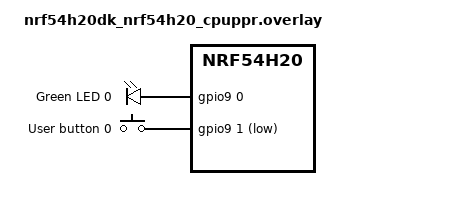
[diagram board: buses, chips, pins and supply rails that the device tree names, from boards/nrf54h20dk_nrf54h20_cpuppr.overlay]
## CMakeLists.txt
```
# SPDX-License-Identifier: Apache-2.0

cmake_minimum_required(VERSION 3.20.0)
find_package(Zephyr REQUIRED HINTS $ENV{ZEPHYR_BASE})
project(VS_Code)

# BLE 低功耗从机用 main2.c；按钮 demo 用 main.c（需改回 main.c 再编译）
target_sources(app PRIVATE src/main.c)
```

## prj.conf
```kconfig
# 关闭串口和控制台，降低功耗（板级默认启用了 UART）
CONFIG_SERIAL=n
CONFIG_CONSOLE=n
CONFIG_UART_CONSOLE=n

# GPIO HAL 依赖（P0 引脚控制）
CONFIG_GPIO=y
```

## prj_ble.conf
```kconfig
# BLE 从机 — 极致低功耗（main2.c 用）
#
# 必须用本文件构建，否则会报 undefined reference to bt_gatt_attr_read_service / bt_gatt_attr_read_chrc：
#   west build -b <board> -- -DCONFIG_FILE=prj_ble.conf
# 且不要使用“关闭 RADIO”的 overlay。
#
CONFIG_BT=y
CONFIG_BT_HOST=y
CONFIG_BT_PERIPHERAL=y
CONFIG_BT_GATT_SERVER=y
CONFIG_BT_DEVICE_NAME="IOTrigger"
CONFIG_BT_MAX_CONN=1
CONFIG_BT_MAX_PAIRED=0

# 长连接间隔 + Slave Latency，由代码里 bt_conn_param_update 请求
CONFIG_BT_CONN_PARAM_UPDATE=y

# 关闭串口/控制台
CONFIG_SERIAL=n
CONFIG_CONSOLE=n
CONFIG_UART_CONSOLE=n

# 不启用 GPIO/TIMER/GPIOTE 等（IO 由你处理）
# CONFIG_GPIO 按需保留，若你只在应用里用 HAL 操作 P0 可不依赖 Zephyr GPIO
```

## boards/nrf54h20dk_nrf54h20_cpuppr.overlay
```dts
/* SPDX-License-Identifier: Apache-2.0 */

#include <zephyr/dt-bindings/gpio/gpio.h>
#include <zephyr/dt-bindings/input/input-event-codes.h>

/ {
	aliases {
		led0 = &led0;
		button0 = &button_0;
	};

	leds {
		compatible = "gpio-leds";
		led0: led_0 {
			gpios = <&gpio9 0 GPIO_ACTIVE_HIGH>;
			label = "Green LED 0";
		};
	};

	gpio_keys {
		compatible = "gpio-keys";
		button_0: button_0 {
			label = "User button 0";
			/* 上拉 + 低电平有效（按下时接地） */
			gpios = <&gpio9 1 (GPIO_PULL_UP | GPIO_ACTIVE_LOW)>;
			zephyr,code = <INPUT_KEY_0>;
		};
	};
};

&gpiote130 {
	status = "okay";
};

&gpio9 {
	status = "okay";
};
```

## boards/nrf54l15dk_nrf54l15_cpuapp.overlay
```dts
/*
 * 默认 overlay：不关闭 RADIO，供 main2.c（BLE 从机）使用。
 * 构建 main.c 按钮 demo 且要关 RADIO 时请用：
 *   -DOVERLAY_FILE=boards/nrf54l15dk_nrf54l15_cpuapp_button.overlay
 */

/*
 * 让 P1.13（BUTTON0）使用低功耗 SENSE 边沿检测
 * 而非 GPIOTE 通道（GPIOTE 通道需要 HFCLK 持续运行 ~300µA）
 * SENSE 机制使用 32.768kHz 时钟采样，空闲时 HFCLK 可关闭
 * BIT(13) = 0x2000
 */
&gpio1 {
	sense-edge-mask = <0x2000>;
};
```

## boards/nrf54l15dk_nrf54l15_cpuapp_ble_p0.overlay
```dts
/*
 * BLE 控制 P0.04 翻转用 overlay
 * 不关闭 RADIO/BT，不启用 PERI 域 TIMER20/21、GPIOTE20
 * P0.04 通过 LP 域（gpio0）控制
 */
/ {
	aliases {
		led-p0-04 = &led_p0_04;
	};
	led_p0_04: led_p0_04 {
		compatible = "gpio-leds";
		gpios = <&gpio0 4 GPIO_ACTIVE_HIGH>;
	};
};

/* 不启用 PERI 域定时器/GPIOTE20，保持与主 overlay 的 sense-edge 等可按需叠加 */
```

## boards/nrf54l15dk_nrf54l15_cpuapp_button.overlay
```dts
/* 关闭 RADIO，仅用于 main.c 按钮低功耗 demo */

&radio {
	status = "disabled";
};

&ieee802154 {
	status = "disabled";
};

&bt_hci_sdc {
	status = "disabled";
};
```

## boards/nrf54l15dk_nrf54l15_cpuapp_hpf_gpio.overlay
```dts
/*
 * Copyright (c) 2024 Nordic Semiconductor ASA
 *
 * SPDX-License-Identifier: LicenseRef-Nordic-5-Clause
 */

#include <zephyr/dt-bindings/gpio/gpio.h>
#include <zephyr/dt-bindings/input/input-event-codes.h>

&led0 {
	gpios = <&hpf_gpio 9 GPIO_ACTIVE_HIGH>;
};

/ {
	aliases {
		button0 = &button_0;
	};

	gpio_keys {
		compatible = "gpio-keys";
		button_0: button_0 {
			label = "User button 0";
			/* 上拉 + 低电平有效（按下时接地） */
			gpios = <&hpf_gpio 8 (GPIO_PULL_UP | GPIO_ACTIVE_LOW)>;
			zephyr,code = <INPUT_KEY_0>;
		};
	};
};
```

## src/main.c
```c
/*
 * 极致低功耗 LP 域定时器触发 P0.04 翻转
 *
 * 功能：
 *   GRTC（LP 域全局实时计数器）每 3s 触发一次翻转序列
 *   每次序列：P0.04 每 300ms 翻转一次，共 6 次
 *   定时间隔、翻转间隔、翻转次数均为变量可调
 *
 * 电源域分析（nRF54L15 Datasheet §Power domains）：
 *   ┌─────────┬─────────────────────────────────────┬──────────┐
 *   │ 域      │ 外设                                │ 本方案   │
 *   ├─────────┼─────────────────────────────────────┼──────────┤
 *   │ MCU (0) │ CPU, CACHE                          │ 必须     │
 *   │ RADIO(1)│ RADIO                               │ 不启用   │
 *   │ PERI (2)│ TIMER20-24, GPIOTE20, UART/SPI, P1 │ 不启用   │
 *   │ LP  (3) │ GRTC, P0                            │ ★ 使用   │
 *   └─────────┴─────────────────────────────────────┴──────────┘
 *
 * 功耗优化策略：
 *   - GRTC 运行在 LFCLK（32.768kHz），无需 HFCLK
 *   - P0.04 属于 LP 域，直接 GPIO HAL 翻转
 *   - 空闲时 System ON IDLE（约 2.9µA with GRTC + 256KB RAM）
 *   - 不启用 PERI 域（无 TIMER20/21、GPIOTE20、HFCLK）
 *
 * CPU 介入分析（每 ~4.8s 周期）：
 *   3s 休眠结束 → 中断 1 次（启动翻转序列）
 *   300ms × 6 翻转 → 中断 6 次（GPIO toggle + 计数，~2µs/次）
 *   共 7 次唤醒，总 CPU 时间 ~14µs / 4.8s
 *
 * 注：GRTC 是全局外设（base 0x400E2000），其 PUBLISH 寄存器不直接
 *     连接 DPPIC30，无法用 DPPI30 → GPIOTE30 实现纯硬件翻转。
 *     由于 CPU 已因计数需求而唤醒，ISR 中直接 toggle 是等效最优解。
 */

#include <zephyr/kernel.h>
#include <zephyr/drivers/timer/nrf_grtc_timer.h>
#include <hal/nrf_gpio.h>

/* ===== 可配置参数（运行时可调） ===== */
static uint32_t cycle_interval_ms  = 3000;  /* 周期间隔，默认 3s */
static uint32_t toggle_interval_ms = 300;   /* 翻转间隔，默认 300ms */
static uint32_t toggle_count       = 6;     /* 每周期翻转次数 */

/* ===== 引脚定义（LP 域） ===== */
#define OUTPUT_PIN    NRF_GPIO_PIN_MAP(0, 1) /* P0.01，属于 LP 域 */

/* ===== GRTC 频率（SYSCOUNTER 运行在 1 MHz） ===== */
#define GRTC_FREQ_HZ  1000000UL

/* ===== 内部状态 ===== */
static int32_t  grtc_chan;          /* Zephyr 分配的 GRTC CC 通道 */
static volatile uint32_t remaining; /* 剩余翻转次数 */

/* 毫秒转 GRTC ticks（1 MHz → 1 tick = 1µs） */
#define MS_TO_TICKS(ms) ((uint64_t)(ms) * (GRTC_FREQ_HZ / 1000))

/* 前向声明 */
static void on_cycle_compare(int32_t id, uint64_t exp, void *ctx);
static void on_toggle_compare(int32_t id, uint64_t exp, void *ctx);

/* ================================================================
 * on_cycle_compare() — 周期到达，启动翻转序列
 *
 * 3s 定时到期 → 初始化翻转计数 → 设置首次翻转 CC
 * ================================================================ */
static void on_cycle_compare(int32_t id, uint64_t exp, void *ctx)
{
	ARG_UNUSED(id);
	ARG_UNUSED(ctx);

	remaining = toggle_count;

	/* 第一次翻转在 toggle_interval_ms 后 */
	z_nrf_grtc_timer_set(grtc_chan,
		exp + MS_TO_TICKS(toggle_interval_ms),
		on_toggle_compare, NULL);
}

/* ================================================================
 * on_toggle_compare() — 每次翻转的 GRTC compare 回调
 *
 * 每次 ~2µs：GPIO toggle（1 指令）+ 计数 + 设置下次 CC
 * ================================================================ */
static void on_toggle_compare(int32_t id, uint64_t exp, void *ctx)
{
	ARG_UNUSED(id);
	ARG_UNUSED(ctx);

	nrf_gpio_pin_toggle(OUTPUT_PIN);
	remaining--;

	if (remaining > 0) {
		/* 下一次翻转 */
		z_nrf_grtc_timer_set(grtc_chan,
			exp + MS_TO_TICKS(toggle_interval_ms),
			on_toggle_compare, NULL);
	} else {
		/* 翻转序列完成：确保 P0.04 归低（偶数次已为低，奇数次强制拉低） */
		nrf_gpio_pin_clear(OUTPUT_PIN);

		/* 设置下一个周期 */
		z_nrf_grtc_timer_set(grtc_chan,
			exp + MS_TO_TICKS(cycle_interval_ms),
			on_cycle_compare, NULL);
	}
}

/* ================================================================ */
int main(void)
{
	/* P0.04 默认输出低电平 */
	nrf_gpio_cfg_output(OUTPUT_PIN);
	nrf_gpio_pin_clear(OUTPUT_PIN);

	/* 分配 GRTC CC 通道（Zephyr 管理，避免与系统定时器冲突） */
	grtc_chan = z_nrf_grtc_timer_chan_alloc();
	if (grtc_chan < 0) {
		return -1;
	}

	/* 启动第一个周期定时 */
	uint64_t now = z_nrf_grtc_timer_read();

	z_nrf_grtc_timer_set(grtc_chan,
		now + MS_TO_TICKS(cycle_interval_ms),
		on_cycle_compare, NULL);

	/* CPU 进入永久休眠（由 GRTC compare 中断唤醒） */
	k_sleep(K_FOREVER);
	return 0;
}
```

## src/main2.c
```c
/*
 * 极致低功耗 BLE 从机 — 手机写 GATT 触发（IO 由你处理）
 *
 * 功能：广播 + 可连接，一个自定义 Service + 一个 Write 特征。
 *       手机写入该特征时触发（回调里不操作 IO，你在别处处理）。
 * 功耗：长连接间隔 800ms + Slave Latency 4，无串口/控制台。
 */

#include <zephyr/kernel.h>
#include <zephyr/bluetooth/bluetooth.h>
#include <zephyr/bluetooth/conn.h>
#include <zephyr/bluetooth/gatt.h>
#include <zephyr/bluetooth/uuid.h>

/* 自定义 Service / Characteristic UUID（16-bit 便于 nRF Connect 识别） */
#define BT_UUID_IO_TRIGGER_SVC_VAL  0x1234
#define BT_UUID_IO_TRIGGER_CHRC_VAL 0x1235

#define BT_UUID_IO_TRIGGER_SVC  BT_UUID_DECLARE_16(BT_UUID_IO_TRIGGER_SVC_VAL)
#define BT_UUID_IO_TRIGGER_CHRC BT_UUID_DECLARE_16(BT_UUID_IO_TRIGGER_CHRC_VAL)

/* 连接参数：800ms 间隔，Slave Latency 4，满足 1 秒内响应且低功耗 */
#define CONN_INTERVAL_800MS  640   /* 800 / 1.25 */
#define CONN_LATENCY         4
#define CONN_TIMEOUT_MS      4000  /* 单位 10ms → 400 */

static const char device_name[] = "IOTrigger";
static struct bt_conn *current_conn;
static const struct bt_data ad[] = {
	BT_DATA_BYTES(BT_DATA_FLAGS, (BT_LE_AD_GENERAL | BT_LE_AD_NO_BREDR)),
	BT_DATA(BT_DATA_NAME_COMPLETE, device_name, sizeof(device_name) - 1),
};

static ssize_t io_trigger_write(struct bt_conn *conn,
			       const struct bt_gatt_attr *attr,
			       const void *buf, uint16_t len, uint16_t offset,
			       uint8_t flags)
{
	(void)conn;
	(void)attr;
	(void)offset;
	(void)flags;
	/* 手机每次写入会进这里：buf/len 为写入数据。在此处或你扩展的逻辑里做 IO 翻转即可 */
	(void)buf;
	(void)len;
	return len;
}

BT_GATT_SERVICE_DEFINE(io_trigger_svc,
	BT_GATT_PRIMARY_SERVICE(BT_UUID_IO_TRIGGER_SVC),
	BT_GATT_CHARACTERISTIC(BT_UUID_IO_TRIGGER_CHRC,
			       BT_GATT_CHRC_WRITE,
			       BT_GATT_PERM_WRITE,
			       NULL, io_trigger_write, NULL),
);

static void connected(struct bt_conn *conn, uint8_t err)
{
	if (err) {
		return;
	}
	current_conn = bt_conn_ref(conn);

	struct bt_le_conn_param param = {
		.interval_min = CONN_INTERVAL_800MS,
		.interval_max = CONN_INTERVAL_800MS,
		.latency = CONN_LATENCY,
		.timeout = CONN_TIMEOUT_MS / 10,
	};
	(void)bt_conn_le_param_update(conn, &param);
}

static void disconnected(struct bt_conn *conn, uint8_t reason)
{
	if (current_conn) {
		bt_conn_unref(current_conn);
		current_conn = NULL;
	}
}

BT_CONN_CB_DEFINE(conn_cb) = {
	.connected = connected,
	.disconnected = disconnected,
};

int main(void)
{
	int err;

	err = bt_enable(NULL);
	if (err) {
		return 0;
	}

	static const struct bt_le_adv_param adv_param = {
		.options = BT_LE_ADV_OPT_CONN,
	};
	err = bt_le_adv_start(&adv_param, ad, ARRAY_SIZE(ad), NULL, 0);
	if (err) {
		return 0;
	}

	for (;;) {
		k_sleep(K_FOREVER);
	}
	return 0;
}
```
